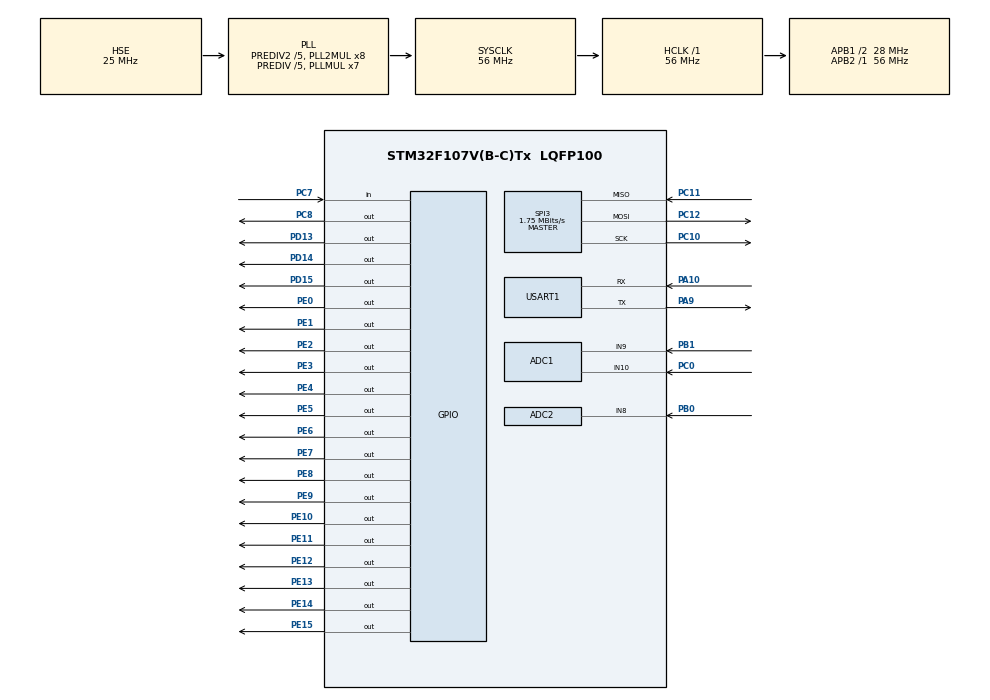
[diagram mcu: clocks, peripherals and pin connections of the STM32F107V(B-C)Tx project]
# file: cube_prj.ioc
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ADC1.Channel-0\#ChannelRegularConversion=ADC_CHANNEL_TEMPSENSOR
ADC1.Channel-1\#ChannelRegularConversion=ADC_CHANNEL_10
ADC1.ContinuousConvMode=ENABLE
ADC1.DataAlign=ADC_DATAALIGN_RIGHT
ADC1.DiscontinuousConvMode=DISABLE
ADC1.EnableAnalogWatchDog=false
ADC1.EnableRegularConversion=ENABLE
ADC1.ExternalTrigConvEdgeChoice=NONE
ADC1.InjNumberOfConversion=0
ADC1.NbrOfConversion=2
ADC1.NbrOfConversionFlag=1
ADC1.Rank-0\#ChannelRegularConversion=1
ADC1.Rank-1\#ChannelRegularConversion=2
ADC1.SamplingTime-0\#ChannelRegularConversion=ADC_SAMPLETIME_239CYCLES_5
ADC1.SamplingTime-1\#ChannelRegularConversion=ADC_SAMPLETIME_239CYCLES_5
ADC1.ScanConvMode=ADC_SCAN_ENABLE
ADC1.master=1
ADC2.Channel-12\#ChannelRegularConversion=ADC_CHANNEL_8
ADC2.ContinuousConvMode=ENABLE
ADC2.DataAlign=ADC_DATAALIGN_RIGHT
ADC2.DiscontinuousConvMode=DISABLE
ADC2.EnableAnalogWatchDog=false
ADC2.EnableRegularConversion=ENABLE
ADC2.ExternalTrigConvEdgeChoice=NONE
ADC2.InjNumberOfConversion=0
ADC2.NbrOfConversion=1
ADC2.NbrOfConversionFlag=1
ADC2.Rank-12\#ChannelRegularConversion=1
ADC2.SamplingTime-12\#ChannelRegularConversion=ADC_SAMPLETIME_239CYCLES_5
ADC2.ScanConvMode=ADC_SCAN_DISABLE
Dma.ADC1.0.Direction=DMA_PERIPH_TO_MEMORY
Dma.ADC1.0.Instance=DMA1_Channel1
Dma.ADC1.0.MemDataAlignment=DMA_MDATAALIGN_HALFWORD
Dma.ADC1.0.MemInc=DMA_MINC_ENABLE
Dma.ADC1.0.Mode=DMA_CIRCULAR
Dma.ADC1.0.PeriphDataAlignment=DMA_PDATAALIGN_HALFWORD
Dma.ADC1.0.PeriphInc=DMA_PINC_DISABLE
Dma.ADC1.0.Priority=DMA_PRIORITY_MEDIUM
Dma.Request0=ADC1
Dma.Request1=USART1_RX
Dma.Request2=USART1_TX
Dma.USART1_RX.1.Direction=DMA_PERIPH_TO_MEMORY
Dma.USART1_RX.1.Instance=DMA1_Channel5
Dma.USART1_RX.1.MemDataAlignment=DMA_MDATAALIGN_BYTE
Dma.USART1_RX.1.MemInc=DMA_MINC_ENABLE
Dma.USART1_RX.1.Mode=DMA_NORMAL
Dma.USART1_RX.1.PeriphDataAlignment=DMA_PDATAALIGN_BYTE
Dma.USART1_RX.1.PeriphInc=DMA_PINC_DISABLE
Dma.USART1_RX.1.Priority=DMA_PRIORITY_LOW
Dma.USART1_TX.2.Direction=DMA_MEMORY_TO_PERIPH
Dma.USART1_TX.2.Instance=DMA1_Channel4
Dma.USART1_TX.2.MemDataAlignment=DMA_MDATAALIGN_BYTE
Dma.USART1_TX.2.MemInc=DMA_MINC_ENABLE
Dma.USART1_TX.2.Mode=DMA_NORMAL
Dma.USART1_TX.2.PeriphDataAlignment=DMA_PDATAALIGN_BYTE
Dma.USART1_TX.2.PeriphInc=DMA_PINC_DISABLE
Dma.USART1_TX.2.Priority=DMA_PRIORITY_LOW
FREERTOS.Tasks01=defaultTask,-3,128,StartDefaultTask,Default;ad_task,0,128,start_ad_task,Default;emwin_task,0,128,start_emwin_task,Default
Mcu.Family=STM32F1
Mcu.Name=STM32F107V(B-C)Tx
Mcu.Package=LQFP100
NVIC.ADC1_2_IRQn=true\:5\:0\:false\:false\:true\:true
NVIC.DMA1_Channel1_IRQn=true\:5\:0\:false\:false\:true\:true
NVIC.DMA1_Channel4_IRQn=true\:5\:0\:false\:false\:true\:true
NVIC.DMA1_Channel5_IRQn=true\:5\:0\:false\:false\:true\:true
NVIC.PriorityGroup=NVIC_PRIORITYGROUP_4
NVIC.RTC_Alarm_IRQn=true\:5\:0\:true\:false\:true\:true
NVIC.RTC_IRQn=true\:5\:0\:false\:false\:true\:true
NVIC.SPI3_IRQn=true\:5\:0\:false\:false\:true\:true
NVIC.TIM6_IRQn=true\:5\:0\:true\:false\:true\:true
NVIC.TIM7_IRQn=true\:0\:0\:false\:false\:true\:false
NVIC.TimeBase=TIM7_IRQn
NVIC.TimeBaseIP=TIM7
OSC_IN.Mode=HSE-External-Oscillator
OSC_IN.Signal=RCC_OSC_IN
OSC_OUT.Mode=HSE-External-Oscillator
OSC_OUT.Signal=RCC_OSC_OUT
PA10.Mode=Asynchronous
PA10.Signal=USART1_RX
PA13.Mode=Serial_Wire
PA13.Signal=SYS_JTMS-SWDIO
PA14.Mode=Serial_Wire
PA14.Signal=SYS_JTCK-SWCLK
PA9.Mode=Asynchronous
PA9.Signal=USART1_TX
PB0.Signal=ADCx_IN8
PB1.Signal=ADCx_IN9
PC0.Signal=ADCx_IN10
PC10.Mode=Full_Duplex_Master
PC10.Signal=SPI3_SCK
PC11.GPIO_PuPd=GPIO_PULLUP
PC11.Mode=Full_Duplex_Master
PC11.Signal=SPI3_MISO
PC12.Mode=Full_Duplex_Master
PC12.Signal=SPI3_MOSI
PC14-OSC32_IN.Mode=LSE-External-Oscillator
PC14-OSC32_IN.Signal=RCC_OSC32_IN
PC15-OSC32_OUT.Mode=LSE-External-Oscillator
PC15-OSC32_OUT.Signal=RCC_OSC32_OUT
PC7.Signal=GPIO_Input
PC8.GPIO_Speed=GPIO_SPEED_FREQ_HIGH
PC8.Signal=GPIO_Output
PD13.Signal=GPIO_Output
PD14.Signal=GPIO_Output
PD15.Signal=GPIO_Output
PE0.GPIO_Speed=GPIO_SPEED_FREQ_HIGH
PE0.Signal=GPIO_Output
PE1.GPIO_Speed=GPIO_SPEED_FREQ_HIGH
PE1.Signal=GPIO_Output
PE10.GPIO_Speed=GPIO_SPEED_FREQ_HIGH
PE10.Signal=GPIO_Output
PE11.GPIO_Speed=GPIO_SPEED_FREQ_HIGH
PE11.Signal=GPIO_Output
PE12.GPIO_Speed=GPIO_SPEED_FREQ_HIGH
PE12.Signal=GPIO_Output
PE13.GPIO_Speed=GPIO_SPEED_FREQ_HIGH
PE13.Signal=GPIO_Output
PE14.GPIO_Speed=GPIO_SPEED_FREQ_HIGH
PE14.Signal=GPIO_Output
PE15.GPIO_Speed=GPIO_SPEED_FREQ_HIGH
PE15.Signal=GPIO_Output
PE2.GPIO_Speed=GPIO_SPEED_FREQ_HIGH
PE2.Signal=GPIO_Output
PE3.GPIO_Speed=GPIO_SPEED_FREQ_HIGH
PE3.Signal=GPIO_Output
PE4.GPIO_Speed=GPIO_SPEED_FREQ_HIGH
PE4.Signal=GPIO_Output
PE5.GPIO_Speed=GPIO_SPEED_FREQ_HIGH
PE5.Signal=GPIO_Output
PE6.GPIO_Speed=GPIO_SPEED_FREQ_HIGH
PE6.Signal=GPIO_Output
PE7.GPIO_Speed=GPIO_SPEED_FREQ_HIGH
PE7.Signal=GPIO_Output
PE8.GPIO_Speed=GPIO_SPEED_FREQ_HIGH
PE8.Signal=GPIO_Output
PE9.GPIO_Speed=GPIO_SPEED_FREQ_HIGH
PE9.Signal=GPIO_Output
ProjectManager.HeapSize=0x400
ProjectManager.StackSize=0x800
ProjectManager.TargetToolchain=MDK-ARM V5
RCC.ADCPresc=RCC_ADCPCLK2_DIV4
RCC.AHBFreq_Value=56000000
RCC.APB1CLKDivider=RCC_HCLK_DIV2
RCC.APB1Freq_Value=28000000
RCC.APB1TimFreq_Value=56000000
RCC.APB2Freq_Value=56000000
RCC.APB2TimFreq_Value=56000000
RCC.HCLKFreq_Value=56000000
RCC.HSEDivPLL=RCC_HSE_PREDIV_DIV5
RCC.HSE_VALUE=25000000
RCC.HSIState=RCC_HSI_ON
RCC.PLLMUL=RCC_PLL_MUL7
RCC.PLLSourceVirtual=RCC_PLLSOURCE_HSE
RCC.Prediv1Source=RCC_PREDIV1_SOURCE_PLL2
RCC.Prediv2=RCC_HSE_PREDIV2_DIV5
RCC.SYSCLKFreq_VALUE=56000000
RCC.SYSCLKSource=RCC_SYSCLKSOURCE_PLLCLK
RCC.USBFreq_Value=37333333.333333336
RTC.AutoPrediv=RTC_AUTO_1_SECOND
RTC.Date=22
RTC.Format=RTC_FORMAT_BCD
RTC.Hours=2
RTC.Minutes=57
RTC.Month=RTC_MONTH_JULY
RTC.Seconds=0
RTC.WeekDay=RTC_WEEKDAY_SATURDAY
RTC.Year=16
SH.ADCx_IN10.0=ADC1_IN10,IN10
SH.ADCx_IN8.0=ADC2_IN8,IN8
SH.ADCx_IN9.0=ADC1_IN9,IN9
SPI3.BaudRatePrescaler=SPI_BAUDRATEPRESCALER_16
SPI3.CLKPhase=SPI_PHASE_2EDGE
SPI3.CLKPolarity=SPI_POLARITY_HIGH
SPI3.CRCCalculation=SPI_CRCCALCULATION_DISABLE
SPI3.CalculateBaudRate=1.75 MBits/s
SPI3.Mode=SPI_MODE_MASTER
TIM6.Period=2
TIM6.Prescaler=35999
TIM6.TIM_MasterOutputTrigger=TIM_TRGO_UPDATE
VP_ADC1_TempSens_Input.Mode=IN-TempSens
VP_CRC_VS_CRC.Mode=CRC_Activate
VP_FREERTOS_VS_ENABLE.Mode=Enabled
VP_RTC_No_RTC_Output.Mode=RTC_OUT_NO
VP_SYS_VS_tim7.Mode=TIM7
VP_TIM6_VS_ClockSourceINT.Mode=Enable_Timer
board=cube_prj

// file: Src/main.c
/**
  ******************************************************************************
  * File Name          : main.c
  * Description        : Main program body
  ******************************************************************************
  *
  * COPYRIGHT(c) 2016 STMicroelectronics
  *
  * Redistribution and use in source and binary forms, with or without modification,
  * are permitted provided that the following conditions are met:
  *   1. Redistributions of source code must retain the above copyright notice,
  *      this list of conditions and the following disclaimer.
  *   2. Redistributions in binary form must reproduce the above copyright notice,
  *      this list of conditions and the following disclaimer in the documentation
  *      and/or other materials provided with the distribution.
  *   3. Neither the name of STMicroelectronics nor the names of its contributors
  *      may be used to endorse or promote products derived from this software
  *      without specific prior written permission.
  *
  * THIS SOFTWARE IS PROVIDED BY THE COPYRIGHT HOLDERS AND CONTRIBUTORS "AS IS"
  * AND ANY EXPRESS OR IMPLIED WARRANTIES, INCLUDING, BUT NOT LIMITED TO, THE
  * IMPLIED WARRANTIES OF MERCHANTABILITY AND FITNESS FOR A PARTICULAR PURPOSE ARE
  * DISCLAIMED. IN NO EVENT SHALL THE COPYRIGHT HOLDER OR CONTRIBUTORS BE LIABLE
  * FOR ANY DIRECT, INDIRECT, INCIDENTAL, SPECIAL, EXEMPLARY, OR CONSEQUENTIAL
  * DAMAGES (INCLUDING, BUT NOT LIMITED TO, PROCUREMENT OF SUBSTITUTE GOODS OR
  * SERVICES; LOSS OF USE, DATA, OR PROFITS; OR BUSINESS INTERRUPTION) HOWEVER
  * CAUSED AND ON ANY THEORY OF LIABILITY, WHETHER IN CONTRACT, STRICT LIABILITY,
  * OR TORT (INCLUDING NEGLIGENCE OR OTHERWISE) ARISING IN ANY WAY OUT OF THE USE
  * OF THIS SOFTWARE, EVEN IF ADVISED OF THE POSSIBILITY OF SUCH DAMAGE.
  *
  ******************************************************************************
  */
#include "stm32f1xx_hal.h"
#include "cmsis_os.h"
#include "adc.h"
#include "crc.h"
#include "dma.h"
#include "rtc.h"
#include "spi.h"
#include "tim.h"
#include "usart.h"
#include "gpio.h"

/* USER CODE BEGIN PV */
/* Private variables ---------------------------------------------------------*/

/* USER CODE END PV */

void SystemClock_Config(void);
void Error_Handler(void);
void MX_FREERTOS_Init(void);

/* USER CODE BEGIN PFP */
/* Private function prototypes -----------------------------------------------*/

/* USER CODE END PFP */

int main(void)
{

  /* MCU Configuration----------------------------------------------------------*/

  /* Reset of all peripherals, Initializes the Flash interface and the Systick. */
  HAL_Init();

  /* Configure the system clock */
  SystemClock_Config();

  /* Initialize all configured peripherals */
  MX_GPIO_Init();
  MX_DMA_Init();
  MX_CRC_Init();
  MX_SPI3_Init();
  MX_TIM6_Init();
  MX_RTC_Init();
  MX_ADC1_Init();
  MX_ADC2_Init();
  MX_USART1_UART_Init();

  /* USER CODE BEGIN 2 */
    HAL_TIM_Base_Start_IT(&htim6);

  /* USER CODE END 2 */

  /* Call init function for freertos objects (in freertos.c) */
  MX_FREERTOS_Init();

  /* Start scheduler */
  osKernelStart();

  /* We should never get here as control is now taken by the scheduler */

  /* Infinite loop */
  while (1)
  {

  }

}

/** System Clock Configuration
*/
void SystemClock_Config(void)
{

  RCC_OscInitTypeDef RCC_OscInitStruct;
  RCC_ClkInitTypeDef RCC_ClkInitStruct;
  RCC_PeriphCLKInitTypeDef PeriphClkInit;

  RCC_OscInitStruct.OscillatorType = RCC_OSCILLATORTYPE_LSI|RCC_OSCILLATORTYPE_HSE;
  RCC_OscInitStruct.HSEState = RCC_HSE_ON;
  RCC_OscInitStruct.HSEPredivValue = RCC_HSE_PREDIV_DIV5;
  RCC_OscInitStruct.LSIState = RCC_LSI_ON;
  RCC_OscInitStruct.Prediv1Source = RCC_PREDIV1_SOURCE_PLL2;
  RCC_OscInitStruct.PLL.PLLState = RCC_PLL_ON;
  RCC_OscInitStruct.PLL.PLLSource = RCC_PLLSOURCE_HSE;
  RCC_OscInitStruct.PLL.PLLMUL = RCC_PLL_MUL7;
  RCC_OscInitStruct.PLL2.PLL2State = RCC_PLL2_ON;
  RCC_OscInitStruct.PLL2.PLL2MUL = RCC_PLL2_MUL8;
  RCC_OscInitStruct.PLL2.HSEPrediv2Value = RCC_HSE_PREDIV2_DIV5;
  if (HAL_RCC_OscConfig(&RCC_OscInitStruct) != HAL_OK)
  {
    Error_Handler();
  }

  RCC_ClkInitStruct.ClockType = RCC_CLOCKTYPE_HCLK|RCC_CLOCKTYPE_SYSCLK
                              |RCC_CLOCKTYPE_PCLK1|RCC_CLOCKTYPE_PCLK2;
  RCC_ClkInitStruct.SYSCLKSource = RCC_SYSCLKSOURCE_PLLCLK;
  RCC_ClkInitStruct.AHBCLKDivider = RCC_SYSCLK_DIV1;
  RCC_ClkInitStruct.APB1CLKDivider = RCC_HCLK_DIV2;
  RCC_ClkInitStruct.APB2CLKDivider = RCC_HCLK_DIV1;
  if (HAL_RCC_ClockConfig(&RCC_ClkInitStruct, FLASH_LATENCY_2) != HAL_OK)
  {
    Error_Handler();
  }

  PeriphClkInit.PeriphClockSelection = RCC_PERIPHCLK_RTC|RCC_PERIPHCLK_ADC;
  PeriphClkInit.RTCClockSelection = RCC_RTCCLKSOURCE_LSI;
  PeriphClkInit.AdcClockSelection = RCC_ADCPCLK2_DIV4;
  if (HAL_RCCEx_PeriphCLKConfig(&PeriphClkInit) != HAL_OK)
  {
    Error_Handler();
  }

  HAL_SYSTICK_Config(HAL_RCC_GetHCLKFreq()/1000);

  HAL_SYSTICK_CLKSourceConfig(SYSTICK_CLKSOURCE_HCLK);

  __HAL_RCC_PLLI2S_ENABLE();

  /* SysTick_IRQn interrupt configuration */
  HAL_NVIC_SetPriority(SysTick_IRQn, 15, 0);
}

void HAL_TIM_PeriodElapsedCallback(TIM_HandleTypeDef *htim)
{
  if (htim->Instance == TIM7) {
    HAL_IncTick();
  }
}

void Error_Handler(void)
{
  while(1)
  {
  }
}

/************************ (C) COPYRIGHT STMicroelectronics *****END OF FILE****/

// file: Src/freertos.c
/**
  ******************************************************************************
  * File Name          : freertos.c
  * Description        : Code for freertos applications
  ******************************************************************************
  *
  * COPYRIGHT(c) 2016 STMicroelectronics
  *
  * Redistribution and use in source and binary forms, with or without modification,
  * are permitted provided that the following conditions are met:
  *   1. Redistributions of source code must retain the above copyright notice,
  *      this list of conditions and the following disclaimer.
  *   2. Redistributions in binary form must reproduce the above copyright notice,
  *      this list of conditions and the following disclaimer in the documentation
  *      and/or other materials provided with the distribution.
  *   3. Neither the name of STMicroelectronics nor the names of its contributors
  *      may be used to endorse or promote products derived from this software
  *      without specific prior written permission.
  *
  * THIS SOFTWARE IS PROVIDED BY THE COPYRIGHT HOLDERS AND CONTRIBUTORS "AS IS"
  * AND ANY EXPRESS OR IMPLIED WARRANTIES, INCLUDING, BUT NOT LIMITED TO, THE
  * IMPLIED WARRANTIES OF MERCHANTABILITY AND FITNESS FOR A PARTICULAR PURPOSE ARE
  * DISCLAIMED. IN NO EVENT SHALL THE COPYRIGHT HOLDER OR CONTRIBUTORS BE LIABLE
  * FOR ANY DIRECT, INDIRECT, INCIDENTAL, SPECIAL, EXEMPLARY, OR CONSEQUENTIAL
  * DAMAGES (INCLUDING, BUT NOT LIMITED TO, PROCUREMENT OF SUBSTITUTE GOODS OR
  * SERVICES; LOSS OF USE, DATA, OR PROFITS; OR BUSINESS INTERRUPTION) HOWEVER
  * CAUSED AND ON ANY THEORY OF LIABILITY, WHETHER IN CONTRACT, STRICT LIABILITY,
  * OR TORT (INCLUDING NEGLIGENCE OR OTHERWISE) ARISING IN ANY WAY OUT OF THE USE
  * OF THIS SOFTWARE, EVEN IF ADVISED OF THE POSSIBILITY OF SUCH DAMAGE.
  *
  ******************************************************************************
  */

#include "FreeRTOS.h"
#include "task.h"
#include "cmsis_os.h"

/* USER CODE BEGIN Includes */
#include "adc_app.h"
#include "ui_drivers.h"
#include "measure_window.h"
#include "start_window.h"

/* USER CODE END Includes */

osThreadId defaultTaskHandle;
osThreadId ad_taskHandle;
osThreadId emwin_taskHandle;

void StartDefaultTask(void const * argument);
void start_ad_task(void const * argument);
void start_emwin_task(void const * argument);

void MX_FREERTOS_Init(void); /* (MISRA C 2004 rule 8.1) */

/* Hook prototypes */

/* Init FreeRTOS */

void MX_FREERTOS_Init(void) {

  /* Create the thread(s) */
  /* definition and creation of defaultTask */
  osThreadDef(defaultTask, StartDefaultTask, osPriorityIdle, 0, 128);
  defaultTaskHandle = osThreadCreate(osThread(defaultTask), NULL);

  /* definition and creation of ad_task */
  osThreadDef(ad_task, start_ad_task, osPriorityNormal, 0, 128);
  ad_taskHandle = osThreadCreate(osThread(ad_task), NULL);

  /* definition and creation of emwin_task */
  osThreadDef(emwin_task, start_emwin_task, osPriorityNormal, 0, 128);
  emwin_taskHandle = osThreadCreate(osThread(emwin_task), NULL);

}

/* StartDefaultTask function */
void StartDefaultTask(void const * argument)
{

  for(;;)
  {
    osDelay(1);
  }
}

/* start_ad_task function */
void start_ad_task(void const * argument)
{
  /* USER CODE BEGIN start_ad_task */
    ADC_start_convert();

  /* Infinite loop */
    for(;;)
    {
//        display_sensor_value(100, 50);
        osDelay(1);
    }
  /* USER CODE END start_ad_task */
}

/* start_emwin_task function */
void start_emwin_task(void const * argument)
{
  /* USER CODE BEGIN start_emwin_task */
    user_interface_config();

    toggle_interface(NO_HWIN, measure_window_info, TIMER_ENABLE, TIMER_PERIOD);
  /* Infinite loop */
    for(;;)
    {
        osDelay(1);
    }
  /* USER CODE END start_emwin_task */
}

/************************ (C) COPYRIGHT STMicroelectronics *****END OF FILE****/
